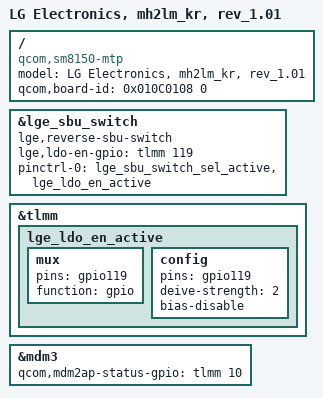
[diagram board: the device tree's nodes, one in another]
/*
 * Copyright (c) 2018, The Linux Foundation. All rights reserved.
 *
 * This program is free software; you can redistribute it and/or modify
 * it under the terms of the GNU General Public License version 2 and
 * only version 2 as published by the Free Software Foundation.
 *
 * This program is distributed in the hope that it will be useful,
 * but WITHOUT ANY WARRANTY; without even the implied warranty of
 * MERCHANTABILITY or FITNESS FOR A PARTICULAR PURPOSE.  See the
 * GNU General Public License for more details.
 */

/dts-v1/;
/plugin/;

#include "sm8150-mh2lm.dtsi"
#include "sm8150-mh2lm-5G_modem.dtsi"
#include "sm8150-mh2lm-sound_kr_rev-b.dtsi"
#include "sm8150-mh2lm-fingerprint.dtsi"
#include "sm8150-mh2lm-tdmb.dtsi"
#include "../sm8150-camera/sm8150-mh2lm-camera_rev-1.0.dtsi"
#include "sm8150-mh2lm_kr-pm.dtsi"

/ {
	model = "LG Electronics, mh2lm_kr, rev_1.01";
	compatible = "qcom,sm8150-mtp", "qcom,sm8150", "qcom,mtp";
	qcom,board-id = <0x010C0108 0>;
};

&lge_sbu_switch {
	lge,reverse-sbu-switch;
        lge,ldo-en-gpio = <&tlmm 119 0>;

        pinctrl-0 = <&lge_sbu_switch_sel_active &lge_ldo_en_active>;
};

&tlmm {
        lge_ldo_en_active: lge_ldo_en_active {
                mux {
                        pins = "gpio119";
                        function = "gpio";
                };

                config {
                        pins = "gpio119";
                        deive-strength = <2>;
                        bias-disable;
                };
        };
};

&mdm3 {
	qcom,mdm2ap-status-gpio   = <&tlmm 10 0x00>;
};
